# nrf52 register map
Vendor: Nordic Semiconductor; Series: nrf52; File version: 1
CPU: CM4 r0p1, little endian, MPU, FPU, 3 interrupt priority bits
Registers are 32-bit, read-write, reset 0x0 unless marked. A register's access mark holds for its fields unless they carry their own. Offsets are from the block's base; [hi:lo] are bit positions; lines under a group give offsets from that group; {n}, {i} and the like mark numbered series; 'fields as' and 'values as' point back to an identical list.

## UICR — User Information Configuration Registers
Base 0x10001000
{0x0+4i} UNUSED{i} (i=0..2) — Unspecified
0x10 UNUSED3 — Unspecified
{0x14+4i} NRFFW[{i}] (i=0..14) reset 0xFFFFFFFF — Description collection[0]: Reserved for Nordic firmware design
  [31:0] NRFFW — Reserved for Nordic firmware design
{0x50+4i} NRFHW[{i}] (i=0..11) reset 0xFFFFFFFF — Description collection[0]: Reserved for Nordic hardware design
  [31:0] NRFHW — Reserved for Nordic hardware design
{0x80+4i} CUSTOMER[{i}] (i=0..31) reset 0xFFFFFFFF — Description collection[0]: Reserved for customer
  [31:0] CUSTOMER — Reserved for customer
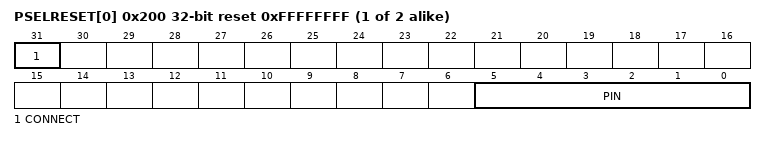
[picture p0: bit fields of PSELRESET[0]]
{0x200+4i} PSELRESET[{i}] (i=0..1) reset 0xFFFFFFFF — Description collection[0]: Mapping of the nRESET function (see POWER chapter for details)
  [31] CONNECT — Connection
    1=Disconnected; 0=Connected
  [5:0] PIN — GPIO number P0.n onto which Reset is exposed
0x208 APPROTECT reset 0xFFFFFFFF — Access Port protection
  [7:0] PALL — Enable or disable Access Port protection. Any other value than 0xFF being written to this field will enable protection.
    255=Disabled; 0=Enabled
0x20C NFCPINS reset 0xFFFFFFFF — Setting of pins dedicated to NFC functionality: NFC antenna or GPIO
  [0] PROTECT — Setting of pins dedicated to NFC functionality
    0=Disabled (Operation as GPIO pins. Same protection as normal GPIO pins); 1=NFC (Operation as NFC antenna pins. Configures the protection for NFC operation)

## BPROT — Block Protect
Base 0x40000000
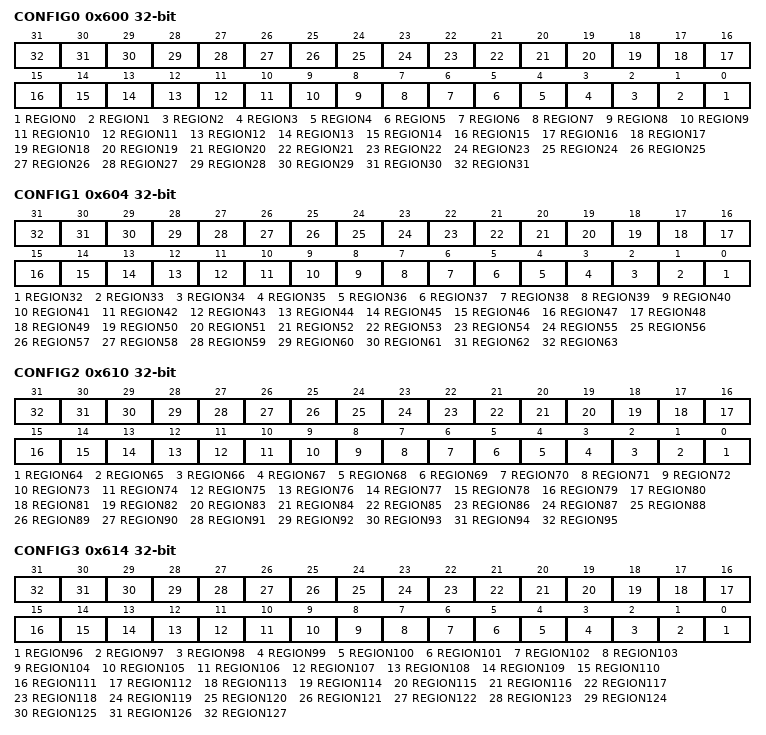
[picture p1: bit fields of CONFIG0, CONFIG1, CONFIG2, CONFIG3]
0x600 CONFIG0 — Block protect configuration register 0
  [all] fields
    0=Disabled (Protection disabled); 1=Enabled (Protection enable)
  [n] REGION{n} (n=0..31) — Enable protection for region {n}. Write '0' has no effect.
0x604 CONFIG1 — Block protect configuration register 1
  [all] fields
    0=Disabled (Protection disabled); 1=Enabled (Protection enabled)
  [n-32] REGION{n} (n=32..63) — Enable protection for region {n}. Write '0' has no effect.
0x608 DISABLEINDEBUG reset 0x1 — Disable protection mechanism in debug interface mode
  [0] DISABLEINDEBUG — Disable the protection mechanism for NVM regions while in debug interface mode. This register will only disable the protection mechanism if the device is in debug interface mode.
    1=Disabled (Disable in debug); 0=Enabled (Enable in debug)
0x60C UNUSED0 — Unspecified
0x610 CONFIG2 — Block protect configuration register 2
  [all] fields
    values as the fields of CONFIG1
  [n-64] REGION{n} (n=64..95) — Enable protection for region {n}. Write '0' has no effect.
0x614 CONFIG3 — Block protect configuration register 3
  [all] fields
    values as the fields of CONFIG1
  [n-96] REGION{n} (n=96..127) — Enable protection for region {n}. Write '0' has no effect.

## SPI0 — Serial Peripheral Interface 0
Base 0x40003000; alternate view of SPIM0
Same registers: SPI1 0x40004000 (alternate view of SPIM1), SPI2 0x40023000 (alternate view of SPIM2)
0x108 EVENTS_READY — TXD byte sent and RXD byte received
  [0] EVENTS_READY
0x304 INTENSET — Enable interrupt
  [2] READY — Write '1' to Enable interrupt for READY event
    on read: 0=Disabled (Read: Disabled); 1=Enabled (Read: Enabled) | on write: 1=Set (Enable)
0x308 INTENCLR — Disable interrupt
  [2] READY — Write '1' to Disable interrupt for READY event
    on read: 0=Disabled (Read: Disabled); 1=Enabled (Read: Enabled) | on write: 1=Clear (Disable)
0x500 ENABLE — Enable SPI
  [3:0] ENABLE — Enable or disable SPI
    0=Disabled (Disable SPI); 1=Enabled (Enable SPI)
0x508 PSEL group — Unspecified
  0x00 SCK reset 0xFFFFFFFF — Pin select for SCK
    [31:0] PSELSCK — Pin number configuration for SPI SCK signal
      0xFFFFFFFF=Disconnected
  0x04 MOSI reset 0xFFFFFFFF — Pin select for MOSI
    [31:0] PSELMOSI — Pin number configuration for SPI MOSI signal
      0xFFFFFFFF=Disconnected
  0x08 MISO reset 0xFFFFFFFF — Pin select for MISO
    [31:0] PSELMISO — Pin number configuration for SPI MISO signal
      0xFFFFFFFF=Disconnected
0x518 RXD ro read-has-side-effects
  [7:0] RXD — RX data received. Double buffered
0x51C TXD
  [7:0] TXD — TX data to send. Double buffered
0x524 FREQUENCY reset 0x4000000 — SPI frequency
  [31:0] FREQUENCY — SPI master data rate
    0x2000000=K125 (125 kbps); 0x4000000=K250 (250 kbps); 0x8000000=K500 (500 kbps); 0x10000000=M1 (1 Mbps); 0x20000000=M2 (2 Mbps); 0x40000000=M4 (4 Mbps); 0x80000000=M8 (8 Mbps)
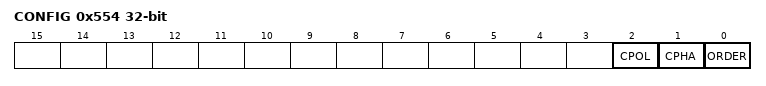
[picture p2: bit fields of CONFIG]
0x554 CONFIG — Configuration register
  [2] CPOL — Serial clock (SCK) polarity
    0=ActiveHigh; 1=ActiveLow
  [1] CPHA — Serial clock (SCK) phase
    0=Leading (Sample on leading edge of clock, shift serial data on trailing edge); 1=Trailing (Sample on trailing edge of clock, shift serial data on leading edge)
  [0] ORDER — Bit order
    0=MsbFirst (Most significant bit shifted out first); 1=LsbFirst (Least significant bit shifted out first)
